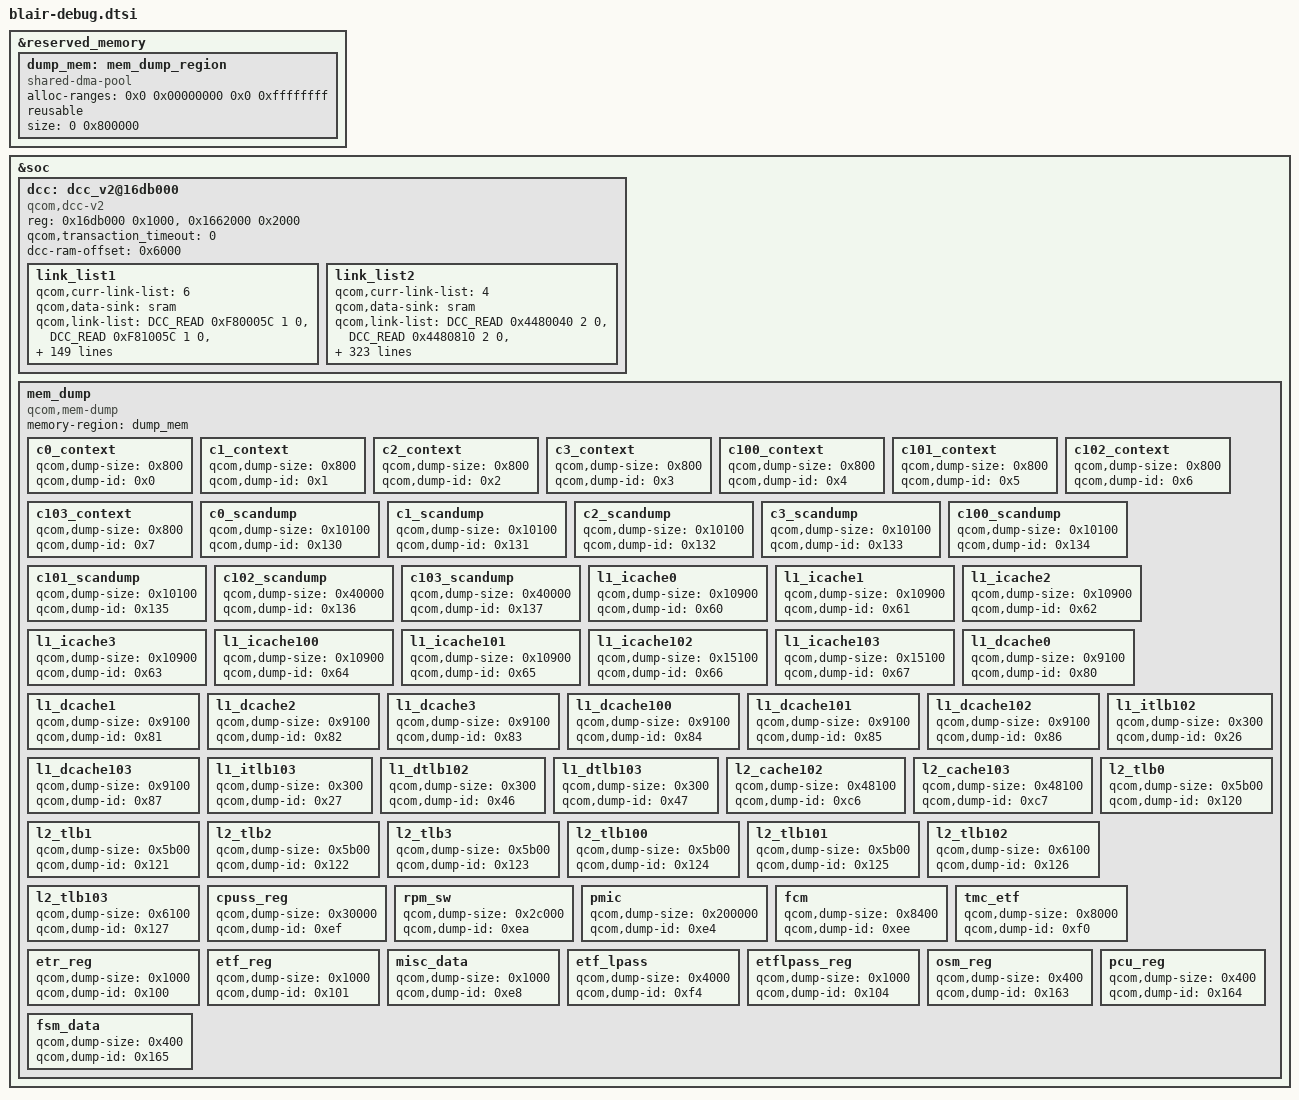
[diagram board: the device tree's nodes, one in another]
#include <dt-bindings/soc/qcom,dcc_v2.h>

&reserved_memory {
	dump_mem: mem_dump_region {
		compatible = "shared-dma-pool";
		alloc-ranges = <0x0 0x00000000 0x0 0xffffffff>;
		reusable;
		size = <0 0x800000>;
	};
};

&soc {
	dcc: dcc_v2@16db000 {
		compatible = "qcom,dcc-v2";
		reg = <0x16db000 0x1000>,
		      <0x1662000 0x2000>;

		qcom,transaction_timeout = <0>;
		reg-names = "dcc-base", "dcc-ram-base";
		dcc-ram-offset = <0x6000>;

		link_list1 {
			qcom,curr-link-list = <6>;
			qcom,data-sink = "sram";
			qcom,link-list = <DCC_READ 0xF80005C 1 0>,
				<DCC_READ 0xF81005C 1 0>,
				<DCC_READ 0xF82005C 1 0>,
				<DCC_READ 0xF83005C 1 0>,
				<DCC_READ 0xF84005C 1 0>,
				<DCC_READ 0xF85005C 1 0>,
				<DCC_READ 0xF86005C 1 0>,
				<DCC_READ 0xF87005C 1 0>,
				<DCC_READ 0xF40003C 1 0>,
				<DCC_READ 0xF800040 1 0>,
				<DCC_READ 0xF80004c 1 0>,
				<DCC_READ 0xF800024 1 0>,
				<DCC_READ 0xF810024 1 0>,
				<DCC_READ 0xF810040 1 0>,
				<DCC_READ 0xF81004C 1 0>,
				<DCC_READ 0xF820024 1 0>,
				<DCC_READ 0xF820040 1 0>,
				<DCC_READ 0xF82004C 1 0>,
				<DCC_READ 0xF830024 1 0>,
				<DCC_READ 0xF830040 1 0>,
				<DCC_READ 0xF83004C 1 0>,
				<DCC_READ 0xF840024 1 0>,
				<DCC_READ 0xF840040 1 0>,
				<DCC_READ 0xF84004C 1 0>,
				<DCC_READ 0xF850024 1 0>,
				<DCC_READ 0xF850040 1 0>,
				<DCC_READ 0xF85004C 1 0>,
				<DCC_READ 0xF860024 1 0>,
				<DCC_READ 0xF860040 1 0>,
				<DCC_READ 0xF86004C 1 0>,
				<DCC_READ 0xF870024 1 0>,
				<DCC_READ 0xF870040 1 0>,
				<DCC_READ 0xF87004C 1 0>,
				<DCC_READ 0xF880024 1 0>,
				<DCC_READ 0xF880040 1 0>,
				<DCC_READ 0xF8801B4 3 0>,
				<DCC_READ 0xF880200 1 0>,
				<DCC_READ 0xFA80000 2 0>,
				<DCC_READ 0xFA82000 2 0>,
				<DCC_READ 0xFA84000 2 0>,
				<DCC_READ 0xF880044 3 0>,
				<DCC_READ 0xF880054 1 0>,
				<DCC_READ 0xF88006C 5 0>,
				<DCC_READ 0x1B60100 11 0>,
				<DCC_READ 0xFBA0C50 1 0>,
				<DCC_READ 0xFBA1090 1 0>,
				<DCC_READ 0xFB90008 1 0>,
				<DCC_READ 0xFB90020 2 0>,
				<DCC_READ 0xFB90070 1 0>,
				<DCC_READ 0xFB90810 1 0>,
				<DCC_READ 0xFB93500 1 0>,
				<DCC_READ 0xFB93A84 1 0>,
				<DCC_READ 0xFBA0008 1 0>,
				<DCC_READ 0xFBA0020 2 0>,
				<DCC_READ 0xFBA0070 1 0>,
				<DCC_READ 0xFBA0810 1 0>,
				<DCC_READ 0xFBA3500 1 0>,
				<DCC_READ 0xFBA3A84 2 0>,
				<DCC_READ 0xF900C14 2 0>,
				<DCC_READ 0xF901C14 2 0>,

				<DCC_READ 0xFD80110 9 0>,
				<DCC_READ 0xFD9001C 3 0>,
				<DCC_READ 0xFD90090 1 0>,
				<DCC_READ 0xFD900B0 2 0>,
				<DCC_READ 0xFD900D8 1 0>,
				<DCC_READ 0xFD900E8 1 0>,
				<DCC_READ 0xFD90300 1 0>,
				<DCC_READ 0xFD90320 1 0>,
				<DCC_READ 0xFD90348 3 0>,
				<DCC_READ 0xFD90360 1 0>,
				<DCC_READ 0xFD90368 2 0>,
				<DCC_READ 0xFD9101C 3 0>,
				<DCC_READ 0xFD91090 1 0>,
				<DCC_READ 0xFD910B0 2 0>,
				<DCC_READ 0xFD910D8 1 0>,
				<DCC_READ 0xFD910E8 1 0>,
				<DCC_READ 0xFD91300 1 0>,
				<DCC_READ 0xFD91320 1 0>,
				<DCC_READ 0xFD91348 3 0>,
				<DCC_READ 0xFD91360 1 0>,
				<DCC_READ 0xFD91368 2 0>,
				<DCC_READ 0xFD9201C 3 0>,
				<DCC_READ 0xFD92090 1 0>,
				<DCC_READ 0xFD920B0 2 0>,
				<DCC_READ 0xFD920D8 1 0>,
				<DCC_READ 0xFD920E8 1 0>,
				<DCC_READ 0xFD92300 1 0>,
				<DCC_READ 0xFD92320 1 0>,
				<DCC_READ 0xFD92348 4 0>,
				<DCC_READ 0xFD92360 1 0>,
				<DCC_READ 0xFD92368 2 0>,
				<DCC_READ 0xFD98004 1 0>,
				<DCC_READ 0xFD98018 3 0>,

				<DCC_READ 0x1880240 1 0>,
				<DCC_READ 0x1880248 1 0>,
				<DCC_READ 0x1880300 8 0>,
				<DCC_READ 0x1880700 4 0>,
				<DCC_READ 0x1880714 3 0>,
				<DCC_READ 0x1881100 2 0>,
				<DCC_READ 0x1880104 2 0>,
				<DCC_READ 0x1880110 1 0>,
				<DCC_READ 0x1880120 8 0>,
				<DCC_READ 0x1900240 5 0>,
				<DCC_READ 0x1900258 1 0>,
				<DCC_READ 0x1900500 8 0>,
				<DCC_READ 0x1900900 1 0>,
				<DCC_READ 0x1900D00 2 0>,
				<DCC_READ 0x1900000 1 0>,
				<DCC_READ 0x1900010 1 0>,
				<DCC_READ 0x1900020 8 0>,
				<DCC_READ 0x1480014 1 0>,
				<DCC_READ 0x1480140 1 0>,
				<DCC_READ 0x1481140 1 0>,

				<DCC_READ 0xF400038 1 0>,
				<DCC_READ 0xF41000C 1 0>,
				<DCC_READ 0xF400438 1 0>,
				<DCC_READ 0xF800058 1 0>,
				<DCC_READ 0xF810058 1 0>,
				<DCC_READ 0xF820058 1 0>,
				<DCC_READ 0xF830058 1 0>,
				<DCC_READ 0xF840058 1 0>,
				<DCC_READ 0xF850058 1 0>,
				<DCC_READ 0xF860058 1 0>,
				<DCC_READ 0xF870058 1 0>,
				<DCC_READ 0xF800060 1 0>,
				<DCC_READ 0xF810060 1 0>,
				<DCC_READ 0xF820060 1 0>,
				<DCC_READ 0xF830060 1 0>,
				<DCC_READ 0xF840060 1 0>,
				<DCC_READ 0xF850060 1 0>,
				<DCC_READ 0xF860060 1 0>,
				<DCC_READ 0xF870060 1 0>,
				<DCC_READ 0xF880060 1 0>,
				<DCC_READ 0xF600440 1 0>,
				<DCC_READ 0xF60043C 1 0>,
				<DCC_READ 0xF600404 1 0>,
				<DCC_READ 0x4407000 5 0>,
				<DCC_READ 0x4402000 2 0>,
				<DCC_READ 0xF200104 29 0>,
				<DCC_READ 0xF200184 29 0>,
				<DCC_READ 0xF200204 29 0>,
				<DCC_READ 0xF200284 29 0>,
				<DCC_READ 0xF200200 1 0>,
				<DCC_READ 0xF25C000 1 0>,
				<DCC_READ 0xF27C000 1 0>,
				<DCC_READ 0xF29C000 1 0>,
				<DCC_READ 0xF2BC000 1 0>,
				<DCC_READ 0xF2DC000 1 0>,
				<DCC_READ 0xF2FC000 1 0>,
				<DCC_READ 0xF31C000 1 0>,
				<DCC_READ 0xF33C000 1 0>;
		};

		link_list2 {
			qcom,curr-link-list = <4>;
			qcom,data-sink = "sram";
			qcom,link-list = <DCC_READ 0x4480040 2 0>,
				<DCC_READ 0x4480810 2 0>,
				<DCC_READ 0x4488100 1 0>,
				<DCC_READ 0x4488400 2 0>,
				<DCC_READ 0x4488410 1 0>,
				<DCC_READ 0x4488420 2 0>,
				<DCC_READ 0x4488430 2 0>,
				<DCC_READ 0x4488440 2 0>,
				<DCC_READ 0x4488450 1 0>,
				<DCC_READ 0x448c100 1 0>,
				<DCC_READ 0x448c400 2 0>,
				<DCC_READ 0x448c410 1 0>,
				<DCC_READ 0x448c420 2 0>,
				<DCC_READ 0x448c430 2 0>,
				<DCC_READ 0x448c440 2 0>,
				<DCC_READ 0x448c450 1 0>,
				<DCC_READ 0x4490100 1 0>,
				<DCC_READ 0x4490400 2 0>,
				<DCC_READ 0x4490410 1 0>,
				<DCC_READ 0x4490420 2 0>,
				<DCC_READ 0x4490430 2 0>,
				<DCC_READ 0x4490440 2 0>,
				<DCC_READ 0x4490450 1 0>,
				<DCC_READ 0x4494100 1 0>,
				<DCC_READ 0x4494400 2 0>,
				<DCC_READ 0x4494410 1 0>,
				<DCC_READ 0x4494420 2 0>,
				<DCC_READ 0x4494430 2 0>,
				<DCC_READ 0x4494440 2 0>,
				<DCC_READ 0x4494450 1 0>,
				<DCC_READ 0x4498100 1 0>,
				<DCC_READ 0x4498400 2 0>,
				<DCC_READ 0x4498410 1 0>,
				<DCC_READ 0x4498420 2 0>,
				<DCC_READ 0x4498430 2 0>,
				<DCC_READ 0x4498440 2 0>,
				<DCC_READ 0x4498450 1 0>,
				<DCC_READ 0x449c400 2 0>,
				<DCC_READ 0x449c420 2 0>,
				<DCC_READ 0x449c430 1 0>,
				<DCC_READ 0x449c440 2 0>,
				<DCC_READ 0x449c450 1 0>,
				<DCC_READ 0x44a0400 2 0>,
				<DCC_READ 0x44a0420 2 0>,
				<DCC_READ 0x44a0430 1 0>,
				<DCC_READ 0x44a0440 2 0>,
				<DCC_READ 0x44a0450 1 0>,
				<DCC_READ 0x44a4100 1 0>,
				<DCC_READ 0x44a4400 2 0>,
				<DCC_READ 0x44a4410 1 0>,
				<DCC_READ 0x44a4420 2 0>,
				<DCC_READ 0x44a4430 2 0>,
				<DCC_READ 0x44a4440 2 0>,
				<DCC_READ 0x44a4450 1 0>,
				<DCC_READ 0x44b0020 1 0>,
				<DCC_READ 0x44b0100 1 0>,
				<DCC_READ 0x44b0120 5 0>,
				<DCC_READ 0x44b0140 1 0>,
				<DCC_READ 0x44b0450 1 0>,
				<DCC_READ 0x44b0500 1 0>,
				<DCC_READ 0x44b0520 1 0>,
				<DCC_READ 0x44b0560 1 0>,
				<DCC_READ 0x44b05a0 1 0>,
				<DCC_READ 0x44b0710 1 0>,
				<DCC_READ 0x44b0720 1 0>,
				<DCC_READ 0x44b0a40 1 0>,
				<DCC_READ 0x44b1800 1 0>,
				<DCC_READ 0x44b408c 1 0>,
				<DCC_READ 0x44b409c 3 0>,
				<DCC_READ 0x44b40b8 1 0>,
				<DCC_READ 0x44b5070 2 0>,
				<DCC_READ 0x44bc020 1 0>,
				<DCC_READ 0x44bc100 1 0>,
				<DCC_READ 0x44bc120 4 0>,
				<DCC_READ 0x44bc140 1 0>,
				<DCC_READ 0x44bc450 1 0>,
				<DCC_READ 0x44bc500 1 0>,
				<DCC_READ 0x44bc520 1 0>,
				<DCC_READ 0x44bc560 1 0>,
				<DCC_READ 0x44bc5a0 1 0>,
				<DCC_READ 0x44bc710 1 0>,
				<DCC_READ 0x44bc720 1 0>,
				<DCC_READ 0x44bca40 1 0>,
				<DCC_READ 0x44bd800 1 0>,
				<DCC_READ 0x44c008c 1 0>,
				<DCC_READ 0x44c009c 3 0>,
				<DCC_READ 0x44c00b8 1 0>,
				<DCC_READ 0x44c1070 2 0>,
				<DCC_READ 0x44c8220 1 0>,
				<DCC_READ 0x44c8400 7 0>,
				<DCC_READ 0x44c8420 9 0>,
				<DCC_READ 0x44c9800 1 0>,
				<DCC_READ 0x44d0000 1 0>,
				<DCC_READ 0x44d0020 1 0>,
				<DCC_READ 0x44d0030 1 0>,
				<DCC_READ 0x44d0100 1 0>,
				<DCC_READ 0x44d0108 2 0>,
				<DCC_READ 0x44d0400 1 0>,
				<DCC_READ 0x44d0410 1 0>,
				<DCC_READ 0x44d0420 1 0>,
				<DCC_READ 0x44d1800 1 0>,
				<DCC_READ 0x450002c 2 0>,
				<DCC_READ 0x4500094 1 0>,
				<DCC_READ 0x450009c 1 0>,
				<DCC_READ 0x45000c4 2 0>,
				<DCC_READ 0x45003dc 1 0>,
				<DCC_READ 0x45005d8 1 0>,
				<DCC_READ 0x450202c 2 0>,
				<DCC_READ 0x4502094 1 0>,
				<DCC_READ 0x450209c 1 0>,
				<DCC_READ 0x45020c4 2 0>,
				<DCC_READ 0x45023dc 1 0>,
				<DCC_READ 0x45025d8 1 0>,
				<DCC_READ 0x450302c 2 0>,
				<DCC_READ 0x4503094 1 0>,
				<DCC_READ 0x450309c 1 0>,
				<DCC_READ 0x45030c4 2 0>,
				<DCC_READ 0x45033dc 1 0>,
				<DCC_READ 0x45035d8 1 0>,
				<DCC_READ 0x4506028 2 0>,
				<DCC_READ 0x4506044 1 0>,
				<DCC_READ 0x4506094 1 0>,
				<DCC_READ 0x45061dc 1 0>,
				<DCC_READ 0x45061ec 1 0>,
				<DCC_READ 0x4506608 1 0>,
				<DCC_READ 0x450702c 2 0>,
				<DCC_READ 0x4507094 1 0>,
				<DCC_READ 0x450709c 1 0>,
				<DCC_READ 0x45070c4 2 0>,
				<DCC_READ 0x45073dc 1 0>,
				<DCC_READ 0x45075d8 1 0>,
				<DCC_READ 0x450902c 2 0>,
				<DCC_READ 0x4509094 1 0>,
				<DCC_READ 0x450909c 1 0>,
				<DCC_READ 0x45090c4 2 0>,
				<DCC_READ 0x45093dc 1 0>,
				<DCC_READ 0x45095d8 1 0>,
				<DCC_READ 0x450a02c 2 0>,
				<DCC_READ 0x450a094 3 0>,
				<DCC_READ 0x450a0c4 2 0>,
				<DCC_READ 0x450a3dc 1 0>,
				<DCC_READ 0x450a5d8 1 0>,

				<DCC_READ 0x1429024 1 0>,
				<DCC_READ 0x143600C 1 0>,
				<DCC_READ 0x145B1E8 1 0>,
				<DCC_READ 0x1471154 1 0>,
				<DCC_READ 0x147B03C 1 0>,
				<DCC_READ 0x147C03C 1 0>,
				<DCC_READ 0x147D070 1 0>,
				<DCC_READ 0x147E0A4 1 0>,
				<DCC_READ 0x5991004 1 0>,
				<DCC_READ 0x599100C 2 0>,
				<DCC_READ 0x5991054 1 0>,
				<DCC_READ 0x599106C 2 0>,
				<DCC_READ 0x5991078 1 0>,
				<DCC_READ 0x5991098 2 0>,
				<DCC_READ 0x5991540 1 0>,
				<DCC_READ 0x5992004 1 0>,
				<DCC_READ 0x5993004 1 0>,
				<DCC_READ 0x5994000 2 0>,
				<DCC_READ 0x5995004 1 0>,
				<DCC_READ 0x5996004 1 0>,
				<DCC_READ 0x5997004 1 0>,
				<DCC_READ 0x593D000 1 0>,
				<DCC_READ 0x593C000 1 0>,
				<DCC_READ 0x5900800 1 0>,
				<DCC_READ 0x5900840 4 0>,
				<DCC_READ 0x5900804 1 0>,
				<DCC_READ 0x598EC30 2 0>,
				<DCC_READ 0x59000E0 1 0>,
				<DCC_READ 0x1400000 9 0>,
				<DCC_READ 0x140002C 2 0>,
				<DCC_READ 0x1400038 1 0>,
				<DCC_READ 0x1401000 9 0>,
				<DCC_READ 0x140102C 2 0>,
				<DCC_READ 0x1401038 1 0>,
				<DCC_READ 0x1402000 9 0>,
				<DCC_READ 0x140202C 2 0>,
				<DCC_READ 0x1402038 1 0>,
				<DCC_READ 0x1403000 9 0>,
				<DCC_READ 0x140302C 2 0>,
				<DCC_READ 0x1403038 1 0>,
				<DCC_READ 0x1404000 9 0>,
				<DCC_READ 0x140402C 2 0>,
				<DCC_READ 0x1404038 1 0>,
				<DCC_READ 0x1405000 9 0>,
				<DCC_READ 0x140502C 2 0>,
				<DCC_READ 0x1405038 1 0>,
				<DCC_READ 0x1406000 9 0>,
				<DCC_READ 0x140602C 2 0>,
				<DCC_READ 0x1406038 1 0>,
				<DCC_READ 0x1407000 9 0>,
				<DCC_READ 0x140702C 2 0>,
				<DCC_READ 0x1407038 1 0>,
				<DCC_READ 0x1407044 2 0>,
				<DCC_READ 0x1408000 9 0>,
				<DCC_READ 0x140802C 2 0>,
				<DCC_READ 0x1408038 1 0>,
				<DCC_READ 0x1409000 8 0>,
				<DCC_READ 0x1409030 1 0>,
				<DCC_READ 0x140A000 9 0>,
				<DCC_READ 0x140A02C 2 0>,
				<DCC_READ 0x140A038 1 0>,
				<DCC_READ 0x140B000 9 0>,
				<DCC_READ 0x140B02C 2 0>,
				<DCC_READ 0x140B038 1 0>,
				<DCC_READ 0x140C000 9 0>,
				<DCC_READ 0x140C02C 2 0>,
				<DCC_READ 0x140C038 1 0>,
				<DCC_READ 0x140E000 1 0>,
				<DCC_READ 0x141001C 1 0>,
				<DCC_READ 0x14103EC 1 0>,
				<DCC_READ 0x1414004 2 0>,
				<DCC_READ 0x1414024 1 0>,
				<DCC_READ 0x1415004 2 0>,
				<DCC_READ 0x1415010 1 0>,
				<DCC_READ 0x1415034 1 0>,
				<DCC_READ 0x1416004 2 0>,
				<DCC_READ 0x1416010 1 0>,
				<DCC_READ 0x1416038 1 0>,
				<DCC_READ 0x141A004 2 0>,
				<DCC_READ 0x141F02C 1 0>,
				<DCC_READ 0x141F15C 1 0>,
				<DCC_READ 0x141F28C 1 0>,
				<DCC_READ 0x141F3BC 1 0>,
				<DCC_READ 0x141F4EC 1 0>,
				<DCC_READ 0x141F61C 1 0>,
				<DCC_READ 0x141F74C 1 0>,
				<DCC_READ 0x1427024 1 0>,
				<DCC_READ 0x1429004 2 0>,
				<DCC_READ 0x142A000 2 0>,
				<DCC_READ 0x142A00C 1 0>,
				<DCC_READ 0x142B188 1 0>,
				<DCC_READ 0x1432004 2 0>,
				<DCC_READ 0x1432034 1 0>,
				<DCC_READ 0x1432080 1 0>,
				<DCC_READ 0x1433008 1 0>,
				<DCC_READ 0x1436004 1 0>,
				<DCC_READ 0x1436018 1 0>,
				<DCC_READ 0x1436040 1 0>,
				<DCC_READ 0x1436048 1 0>,
				<DCC_READ 0x143B000 10 0>,
				<DCC_READ 0x143E000 10 0>,
				<DCC_READ 0x1445004 2 0>,
				<DCC_READ 0x1446004 2 0>,
				<DCC_READ 0x1446024 1 0>,
				<DCC_READ 0x1446150 1 0>,
				<DCC_READ 0x1447000 2 0>,
				<DCC_READ 0x1449000 2 0>,
				<DCC_READ 0x1453000 1 0>,
				<DCC_READ 0x1453030 1 0>,
				<DCC_READ 0x1453160 1 0>,
				<DCC_READ 0x1453290 1 0>,
				<DCC_READ 0x14533C0 1 0>,
				<DCC_READ 0x14534F0 1 0>,
				<DCC_READ 0x1453620 1 0>,
				<DCC_READ 0x1457000 2 0>,
				<DCC_READ 0x145700C 1 0>,
				<DCC_READ 0x1458004 2 0>,
				<DCC_READ 0x145A000 2 0>,
				<DCC_READ 0x145A00C 1 0>,
				<DCC_READ 0x145B000 2 0>,
				<DCC_READ 0x145B00C 1 0>,
				<DCC_READ 0x145B204 2 0>,
				<DCC_READ 0x1469000 2 0>,
				<DCC_READ 0x146900C 1 0>,
				<DCC_READ 0x146B000 11 0>,
				<DCC_READ 0x146C000 2 0>,
				<DCC_READ 0x146C00C 1 0>,
				<DCC_READ 0x146F024 1 0>,
				<DCC_READ 0x1472024 1 0>,
				<DCC_READ 0x1475000 2 0>,
				<DCC_READ 0x147500C 1 0>,
				<DCC_READ 0x1477000 5 0>,
				<DCC_READ 0x1478030 1 0>,
				<DCC_READ 0x1479000 2 0>,
				<DCC_READ 0x147900C 1 0>,
				<DCC_READ 0x147A000 2 0>,
				<DCC_READ 0x147A00C 1 0>,
				<DCC_READ 0x147A014 1 0>,
				<DCC_READ 0x147B014 2 0>,
				<DCC_READ 0x147B020 4 0>,
				<DCC_READ 0x147B050 2 0>,
				<DCC_READ 0x147B05C 7 0>,
				<DCC_READ 0x147C000 1 0>,
				<DCC_READ 0x147C014 2 0>,
				<DCC_READ 0x147C020 4 0>,
				<DCC_READ 0x147C050 2 0>,
				<DCC_READ 0x147C05C 7 0>,
				<DCC_READ 0x147D000 1 0>,
				<DCC_READ 0x1482000 2 0>,
				<DCC_READ 0x148200C 1 0>,
				<DCC_READ 0x1483140 1 0>,
				<DCC_READ 0x1487084 2 0>,
				<DCC_READ 0x1490004 2 0>,
				<DCC_READ 0x1490024 2 0>,
				<DCC_READ 0x1495000 2 0>,
				<DCC_READ 0x149500C 1 0>,
				<DCC_READ 0x440C040 9 0>,
				<DCC_READ 0x440C068 2 0>,
				<DCC_READ 0x1410134 1 0>,
				<DCC_READ 0x1410274 1 0>,
				<DCC_READ 0x141027C 2 0>,
				<DCC_READ 0x14103D4 1 0>,
				<DCC_READ 0x1410518 1 0>,
				<DCC_READ 0x1410650 1 0>,
				<DCC_READ 0x1411018 2 0>,
				<DCC_READ 0x141114C 3 0>,
				<DCC_READ 0x141115C 1 0>,
				<DCC_READ 0x1411164 1 0>,
				<DCC_READ 0x141116C 1 0>,
				<DCC_READ 0x141413C 1 0>,
				<DCC_READ 0x141514C 1 0>,
				<DCC_READ 0x1416150 1 0>,
				<DCC_READ 0x1429080 1 0>,
				<DCC_READ 0x142A150 1 0>,
				<DCC_READ 0x142B184 1 0>,
				<DCC_READ 0x143214C 1 0>,
				<DCC_READ 0x1433144 1 0>,
				<DCC_READ 0x1433274 1 0>,
				<DCC_READ 0x1436178 1 0>,
				<DCC_READ 0x1458088 1 0>,
				<DCC_READ 0x0f421000 16 0>,
				<DCC_READ 0x0f421fd0 1 0>,
				<DCC_READ 0x0f8801f0 1 0>;
		};
	};

	mem_dump {
		compatible = "qcom,mem-dump";
		memory-region = <&dump_mem>;

		c0_context {
			qcom,dump-size = <0x800>;
			qcom,dump-id = <0x0>;
		};

		c1_context {
			qcom,dump-size = <0x800>;
			qcom,dump-id = <0x1>;
		};

		c2_context {
			qcom,dump-size = <0x800>;
			qcom,dump-id = <0x2>;
		};

		c3_context {
			qcom,dump-size = <0x800>;
			qcom,dump-id = <0x3>;
		};

		c100_context {
			qcom,dump-size = <0x800>;
			qcom,dump-id = <0x4>;
		};

		c101_context {
			qcom,dump-size = <0x800>;
			qcom,dump-id = <0x5>;
		};

		c102_context {
			qcom,dump-size = <0x800>;
			qcom,dump-id = <0x6>;
		};

		c103_context {
			qcom,dump-size = <0x800>;
			qcom,dump-id = <0x7>;
		};

		c0_scandump {
			qcom,dump-size = <0x10100>;
			qcom,dump-id = <0x130>;
		};

		c1_scandump {
			qcom,dump-size = <0x10100>;
			qcom,dump-id = <0x131>;
		};

		c2_scandump {
			qcom,dump-size = <0x10100>;
			qcom,dump-id = <0x132>;
		};

		c3_scandump {
			qcom,dump-size = <0x10100>;
			qcom,dump-id = <0x133>;
		};

		c100_scandump: c100_scandump {
			qcom,dump-size = <0x10100>;
			qcom,dump-id = <0x134>;
		};

		c101_scandump: c101_scandump {
			qcom,dump-size = <0x10100>;
			qcom,dump-id = <0x135>;
		};

		c102_scandump: c102_scandump {
			qcom,dump-size = <0x40000>;
			qcom,dump-id = <0x136>;
		};

		c103_scandump: c103_scandump {
			qcom,dump-size = <0x40000>;
			qcom,dump-id = <0x137>;
		};

		l1_icache0 {
			qcom,dump-size = <0x10900>;
			qcom,dump-id = <0x60>;
		};

		l1_icache1 {
			qcom,dump-size = <0x10900>;
			qcom,dump-id = <0x61>;
		};

		l1_icache2 {
			qcom,dump-size = <0x10900>;
			qcom,dump-id = <0x62>;
		};

		l1_icache3 {
			qcom,dump-size = <0x10900>;
			qcom,dump-id = <0x63>;
		};

		l1_icache100 {
			qcom,dump-size = <0x10900>;
			qcom,dump-id = <0x64>;
		};

		l1_icache101 {
			qcom,dump-size = <0x10900>;
			qcom,dump-id = <0x65>;
		};

		l1_icache102 {
			qcom,dump-size = <0x15100>;
			qcom,dump-id = <0x66>;
		};

		l1_icache103 {
			qcom,dump-size = <0x15100>;
			qcom,dump-id = <0x67>;
		};

		l1_dcache0 {
			qcom,dump-size = <0x9100>;
			qcom,dump-id = <0x80>;
		};

		l1_dcache1 {
			qcom,dump-size = <0x9100>;
			qcom,dump-id = <0x81>;
		};

		l1_dcache2 {
			qcom,dump-size = <0x9100>;
			qcom,dump-id = <0x82>;
		};

		l1_dcache3 {
			qcom,dump-size = <0x9100>;
			qcom,dump-id = <0x83>;
		};

		l1_dcache100 {
			qcom,dump-size = <0x9100>;
			qcom,dump-id = <0x84>;
		};

		l1_dcache101 {
			qcom,dump-size = <0x9100>;
			qcom,dump-id = <0x85>;
		};

		l1_dcache102 {
			qcom,dump-size = <0x9100>;
			qcom,dump-id = <0x86>;
		};

		l1_dcache103 {
			qcom,dump-size = <0x9100>;
			qcom,dump-id = <0x87>;
		};

		l1_itlb102 {
			qcom,dump-size = <0x300>;
			qcom,dump-id = <0x26>;
		};

		l1_itlb103 {
			qcom,dump-size = <0x300>;
			qcom,dump-id = <0x27>;
		};

		l1_dtlb102 {
			qcom,dump-size = <0x300>;
			qcom,dump-id = <0x46>;
		};

		l1_dtlb103 {
			qcom,dump-size = <0x300>;
			qcom,dump-id = <0x47>;
		};

		l2_cache102 {
			qcom,dump-size = <0x48100>;
			qcom,dump-id = <0xc6>;
		};

		l2_cache103 {
			qcom,dump-size = <0x48100>;
			qcom,dump-id = <0xc7>;
		};

		l2_tlb0 {
			qcom,dump-size = <0x5b00>;
			qcom,dump-id = <0x120>;
		};

		l2_tlb1 {
			qcom,dump-size = <0x5b00>;
			qcom,dump-id = <0x121>;
		};

		l2_tlb2 {
			qcom,dump-size = <0x5b00>;
			qcom,dump-id = <0x122>;
		};

		l2_tlb3 {
			qcom,dump-size = <0x5b00>;
			qcom,dump-id = <0x123>;
		};

		l2_tlb100 {
			qcom,dump-size = <0x5b00>;
			qcom,dump-id = <0x124>;
		};

		l2_tlb101 {
			qcom,dump-size = <0x5b00>;
			qcom,dump-id = <0x125>;
		};

		l2_tlb102 {
			qcom,dump-size = <0x6100>;
			qcom,dump-id = <0x126>;
		};

		l2_tlb103 {
			qcom,dump-size = <0x6100>;
			qcom,dump-id = <0x127>;
		};

		cpuss_reg {
			qcom,dump-size = <0x30000>;
			qcom,dump-id = <0xef>;
		};

		rpm_sw {
			qcom,dump-size = <0x2c000>;
			qcom,dump-id = <0xea>;
		};

		pmic {
			qcom,dump-size = <0x200000>;
			qcom,dump-id = <0xe4>;
		};

		fcm {
			qcom,dump-size = <0x8400>;
			qcom,dump-id = <0xee>;
		};

		tmc_etf {
			qcom,dump-size = <0x8000>;
			qcom,dump-id = <0xf0>;
		};

		etr_reg {
			qcom,dump-size = <0x1000>;
			qcom,dump-id = <0x100>;
		};

		etf_reg {
			qcom,dump-size = <0x1000>;
			qcom,dump-id = <0x101>;
		};

		misc_data {
			qcom,dump-size = <0x1000>;
			qcom,dump-id = <0xe8>;
		};

		etf_lpass {
			qcom,dump-size = <0x4000>;
			qcom,dump-id = <0xf4>;
		};

		etflpass_reg {
			qcom,dump-size = <0x1000>;
			qcom,dump-id = <0x104>;
		};

		osm_reg {
			qcom,dump-size = <0x400>;
			qcom,dump-id = <0x163>;
		};

		pcu_reg {
			qcom,dump-size = <0x400>;
			qcom,dump-id = <0x164>;
		};

		fsm_data {
			qcom,dump-size = <0x400>;
			qcom,dump-id = <0x165>;
		};
	};
};
